VERSION ""

NS_ :

BS_:

BU_: InstrumentalCluster
VAL_TABLE_ PassengerInterierDisplaytbl 3 "NotAvailable" 2 "Errore" 1 "Enable" 0 "Disable" ;
VAL_TABLE_ RearLedDisplayPowertbl 3 "NotAvailable" 2 "Errore" 1 "Enable" 0 "Disable" ;
VAL_TABLE_ DoorSideExterierPowertbl 3 "NotAvailable" 2 "Errore" 1 "Enable" 0 "Disable" ;
VAL_TABLE_ DriverSideInteriorPowertbl 3 "NotAvailable" 2 "Errore" 1 "Enable" 0 "Disable" ;
VAL_TABLE_ DriverSideExterierPowertbl 3 "NotAvailable" 2 "Errore" 1 "Enable" 0 "Disable" ;
VAL_TABLE_ DoorSideInteriorPowertbl 3 "NotAvailable" 2 "Errore" 1 "Enable" 0 "Disable" ;
VAL_TABLE_ FrontLedDisplayPowertbl 3 "NotAvailable" 2 "Errore" 1 "Enable" 0 "Disable" ;
VAL_TABLE_ RebootRequest_TBL 3 "No Action" 2 "Reserved" 1 "RebootRequest" 0 "NoRequest" ;
VAL_TABLE_ ReqeustRebootCancelation_TBL 3 "Not Available" 1 "Started " 0 "Not started" ;
VAL_TABLE_ RequestCanceledReboot_TBL 3 "Not Available" 1 "Canceled" 0 "Not Canceled" ;
VAL_TABLE_ NetToSleepReadyTable 1 "TRUE" 0 "FALSE" ;
VAL_TABLE_ RMReqMode_Table 3 "NA" 2 "FALSE" 1 "TRUE" 0 "NA" ;
VAL_TABLE_ RMModeState_Table 3 "Full recovery" 2 "Flatbed recovery" 1 "Not activated" 0 "NA" ;
VAL_TABLE_ panicAlertDriverReq_Table 3 "NotAvailable" 2 "Reserved" 1 "Panic Alert Requested" 0 "Not requested" ;

BO_ 2348875518 ODM_HMI_SecureStorage: 24 Vector__XXX
 SG_ SecSt_Second_OdometerVal : 160|32@1+ (1,0) [0|0] "" Vector__XXX
 SG_ SecSt_First_OdometerVal : 128|32@1+ (1,0) [0|0] "" Vector__XXX
 SG_ SecSt_Second_Year : 96|7@1+ (1,2000) [2000|2127] "" Vector__XXX
 SG_ SecSt_Second_SPN : 104|20@1+ (1,0) [0|0] "" Vector__XXX
 SG_ SecSt_Second_Seconds : 88|6@1+ (1,0) [0|60] "" Vector__XXX
 SG_ SecSt_Second_Mounth : 124|4@1+ (1,0) [1|12] "" Vector__XXX
 SG_ SecSt_Second_Minutes : 80|6@1+ (1,0) [0|60] "" Vector__XXX
 SG_ SecSt_Second_Hour : 72|5@1+ (1,0) [0|23] "" Vector__XXX
 SG_ SecSt_Second_Day : 64|5@1+ (1,0) [0|31] "" Vector__XXX
 SG_ SecSt_First_Year : 32|7@1+ (1,2000) [2000|2127] "" Vector__XXX
 SG_ SecSt_First_SPN : 40|20@1+ (1,0) [0|1048575] "" Vector__XXX
 SG_ SecSt_First_Seconds : 24|6@1+ (1,0) [0|60] "" Vector__XXX
 SG_ SecSt_First_Mounth : 60|4@1+ (1,0) [1|12] "" Vector__XXX
 SG_ SecSt_First_Minutes : 16|6@1+ (1,0) [0|59] "" Vector__XXX
 SG_ SecSt_First_Hour : 8|5@1+ (1,0) [0|23] "" Vector__XXX
 SG_ SecSt_First_Day : 0|5@1+ (1,0) [1|31] "" Vector__XXX

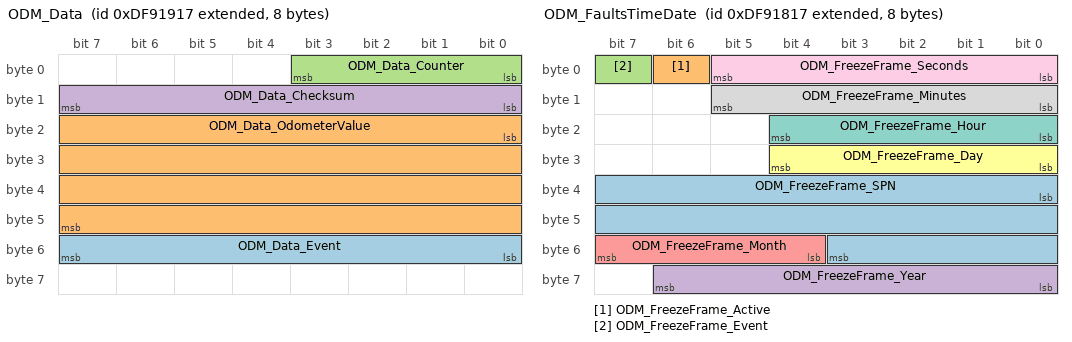
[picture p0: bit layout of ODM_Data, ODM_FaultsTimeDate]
BO_ 2381912343 ODM_Data: 8 Vector__XXX
 SG_ ODM_Data_Event : 48|8@1+ (1,0) [0|0] "" Vector__XXX
 SG_ ODM_Data_OdometerValue : 16|32@1+ (1,0) [0|1700000000] "" Vector__XXX
 SG_ ODM_Data_Counter : 0|4@1+ (1,0) [0|15] "" Vector__XXX
 SG_ ODM_Data_Checksum : 8|8@1+ (1,0) [0|255] "" Vector__XXX

BO_ 2381912087 ODM_FaultsTimeDate: 8 Vector__XXX
 SG_ ODM_FreezeFrame_SPN : 32|20@1+ (1,0) [0|1048575] "" Vector__XXX
 SG_ ODM_FreezeFrame_Active : 6|1@1+ (1,0) [0|1] "" Vector__XXX
 SG_ ODM_FreezeFrame_Event : 7|1@1+ (1,0) [0|1] "" Vector__XXX
 SG_ ODM_FreezeFrame_Year : 56|7@1+ (1,2000) [2000|2127] "" Vector__XXX
 SG_ ODM_FreezeFrame_Month : 52|4@1+ (1,0) [1|12] "" Vector__XXX
 SG_ ODM_FreezeFrame_Day : 24|5@1+ (1,0) [0|31] "" Vector__XXX
 SG_ ODM_FreezeFrame_Hour : 16|5@1+ (1,0) [0|23] "" Vector__XXX
 SG_ ODM_FreezeFrame_Minutes : 8|6@1+ (1,0) [0|59] "" Vector__XXX
 SG_ ODM_FreezeFrame_Seconds : 0|6@1+ (1,0) [0|59] "" Vector__XXX

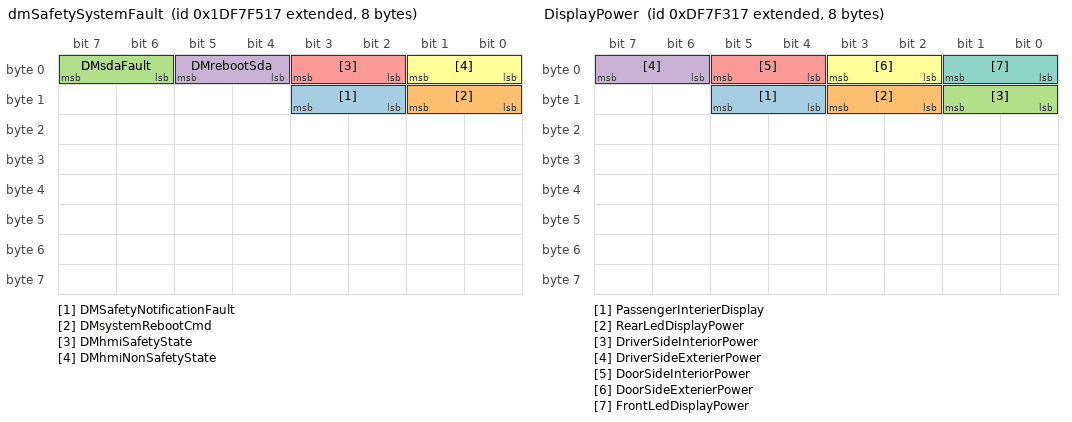
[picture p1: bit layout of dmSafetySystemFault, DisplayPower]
BO_ 2650273047 dmSafetySystemFault: 8 Vector__XXX
 SG_ DMSafetyNotificationFault : 10|2@1+ (1,0) [0|3] "" Vector__XXX
 SG_ DMsystemRebootCmd : 8|2@1+ (1,0) [0|3] "" Vector__XXX
 SG_ DMsdaFault : 6|2@1+ (1,0) [0|3] "" Vector__XXX
 SG_ DMrebootSda : 4|2@1+ (1,0) [0|3] "" Vector__XXX
 SG_ DMhmiSafetyState : 2|2@1+ (1,0) [0|3] "" Vector__XXX
 SG_ DMhmiNonSafetyState : 0|2@1+ (1,0) [0|3] "" Vector__XXX

BO_ 2650747927 HMIConnectivity: 8 Vector__XXX
 SG_ HVPSConnection : 0|1@1+ (1,0) [0|1] "" Vector__XXX

BO_ 2381837079 DisplayPower: 8 Vector__XXX
 SG_ PassengerInterierDisplay : 12|2@1+ (1,0) [0|3] "" Vector__XXX
 SG_ RearLedDisplayPower : 10|2@1+ (1,0) [0|3] "" Vector__XXX
 SG_ DriverSideInteriorPower : 8|2@1+ (1,0) [0|3] "" Vector__XXX
 SG_ DriverSideExterierPower : 6|2@1+ (1,0) [0|3] "" Vector__XXX
 SG_ DoorSideInteriorPower : 4|2@1+ (1,0) [0|3] "" Vector__XXX
 SG_ DoorSideExterierPower : 2|2@1+ (1,0) [0|3] "" Vector__XXX
 SG_ FrontLedDisplayPower : 0|2@1+ (1,0) [0|3] "" Vector__XXX

BO_ 2381836567 UIRebootStop: 8 Vector__XXX
 SG_ RequestCanceledReboot : 0|2@1+ (1,0) [0|3] "" Vector__XXX

BO_ 2381836453 UIRebootRequest: 8 Vector__XXX
 SG_ RebootRequest : 2|2@1+ (1,0) [0|3] "" Vector__XXX
 SG_ ReqeustRebootCancelation : 0|2@1+ (1,0) [0|3] "" Vector__XXX

BO_ 2381846295 VehicleInfo: 8 Vector__XXX
 SG_ CurSpeedLimit : 0|16@1+ (1,0) [0|65535] "" Vector__XXX

BO_ 2381845783 RMRequest: 8 Vector__XXX
 SG_ RMRequest : 0|2@1+ (1,0) [0|3] "" Vector__XXX

BO_ 2381845594 ReqModeState: 8 Vector__XXX
 SG_ RMModeState : 0|2@1+ (1,0) [0|3] "" Vector__XXX

BO_ 2381845159 PanicAlert: 8 Vector__XXX
 SG_ panicAlertDriverReq : 0|2@1+ (1,0) [0|3] "" Vector__XXX

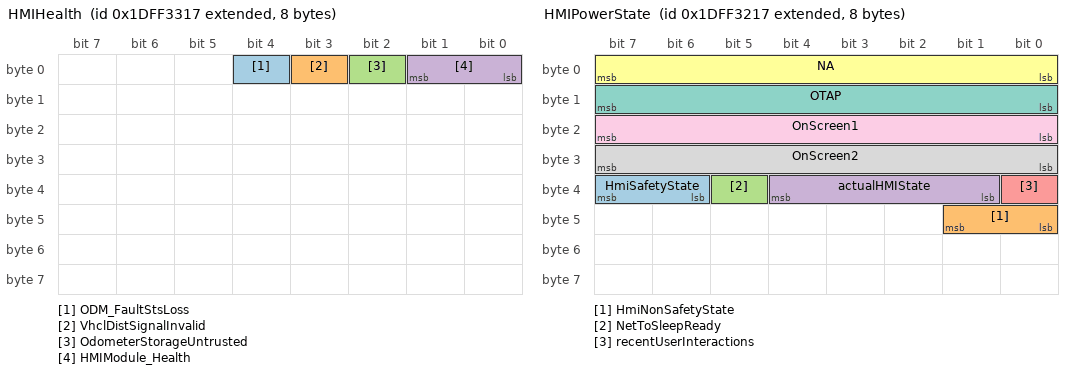
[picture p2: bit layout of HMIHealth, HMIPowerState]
BO_ 2650747671 HMIHealth: 8 Vector__XXX
 SG_ ODM_FaultStsLoss : 4|1@1+ (1,0) [0|1] "" Vector__XXX
 SG_ VhclDistSignalInvalid : 3|1@1+ (1,0) [0|1] "" Vector__XXX
 SG_ OdometerStorageUntrusted : 2|1@1+ (1,0) [0|1] "" Vector__XXX
 SG_ HMIModule_Health : 0|2@1+ (1,0) [0|3] "" Vector__XXX

BO_ 2650747415 HMIPowerState: 8 InstrumentalCluster
 SG_ HmiSafetyState : 38|2@1+ (1,0) [0|3] "" Vector__XXX
 SG_ HmiNonSafetyState : 40|2@1+ (1,0) [0|3] "" Vector__XXX
 SG_ NetToSleepReady : 37|1@1+ (1,0) [0|1] "" Vector__XXX
 SG_ actualHMIState : 33|4@1+ (1,0) [0|15] "" Vector__XXX
 SG_ recentUserInteractions : 32|1@1+ (1,0) [0|1] "" Vector__XXX
 SG_ NA : 0|8@1+ (1,0) [0|1] "" Vector__XXX
 SG_ OTAP : 8|8@1+ (1,0) [0|1] "" Vector__XXX
 SG_ OnScreen2 : 24|8@1+ (1,0) [0|1] "" Vector__XXX
 SG_ OnScreen1 : 16|8@1+ (1,0) [0|1] "" Vector__XXX

CM_ BO_ 2381912343 "Value of odometer travelled distance, stored in HMI backup memory, in meters.
";
CM_ SG_ 2381912343 ODM_Data_Counter "counter signal for E2E protection";
CM_ SG_ 2381912343 ODM_Data_Checksum "Checksum signal for E2E protection";
CM_ BO_ 2381912087 "Data sent from HMI with information about time when particular Odometer DTC has been raised";
CM_ SG_ 2381912087 ODM_FreezeFrame_Event "Which freeze frame is transmited
0 - First security event
1 - Last security event";
CM_ SG_ 2650273047 DMSafetyNotificationFault "CAN Timeout DM";
CM_ SG_ 2650273047 DMsystemRebootCmd "System reboot status";
CM_ SG_ 2650273047 DMsdaFault "SDA fault status";
CM_ SG_ 2650273047 DMrebootSda "Reboot SDA status";
CM_ SG_ 2650273047 DMhmiSafetyState "Safety State system status";
CM_ SG_ 2650273047 DMhmiNonSafetyState "Non Safety State system status";
CM_ SG_ 2650747671 HMIModule_Health "Overal HMI health status";
CM_ BO_ 2650747415 "Power state of HMI as well as OTA state";
CM_ SG_ 2650747415 recentUserInteractions "Any of possible user interactions with HMI was detected during the configured time interval (Boolean value)
1- True,
0 -False";
CM_ SG_ 2650747415 NA "State: 0 - NA, means others flags isn't valid;  1 - OK, means others flags are valid";
CM_ SG_ 2650747415 OTAP "OTA in progress: 1 - true; 0 - false";
CM_ SG_ 2650747415 OnScreen2 "Screen 2 is ON: 1 - true; 0 - false";
CM_ SG_ 2650747415 OnScreen1 "Screen 1 is ON: 1 - true; 0 - false";
BA_DEF_ SG_  "SPN" INT 0 524287;
BA_DEF_ SG_  "GenSigEVName" STRING ;
BA_DEF_ SG_  "GenSigILSupport" ENUM  "No","Yes";
BA_DEF_ SG_  "GenSigSendType" ENUM  "Cyclic","OnWrite","OnWriteWithRepetition","OnChange","OnChangeWithRepetition","IfActive","IfActiveWithRepetition","NoSigSendType";
BA_DEF_ SG_  "SigType" ENUM  "Default","Range","RangeSigned","ASCII","Discrete","Control","ReferencePGN","DTC","StringDelimiter","StringLength","StringLengthControl","MessageCounter","MessageChecksum";
BA_DEF_ BO_  "VFrameFormat" ENUM  "StandardCAN","ExtendedCAN","reserved","J1939PG";
BA_DEF_ BO_  "GenMsgSendType" ENUM  "cyclic","NotUsed","NotUsed","NotUsed","NotUsed","NotUsed","NotUsed","IfActive","noMsgSendType";
BA_DEF_ BO_  "GenMsgRequestable" INT 0 1;
BA_DEF_ BO_  "GenMsgILSupport" ENUM  "No","Yes";
BA_DEF_ BU_  "NmStationAddress" INT 0 255;
BA_DEF_  "ProtocolType" STRING ;
BA_DEF_  "DBName" STRING ;
BA_DEF_  "BusType" STRING ;
BA_DEF_ BO_  "GenMsgCycleTime" INT 0 65535;
BA_DEF_ SG_  "GenSigStartValue" FLOAT -3.4E+038 3.4E+038;
BA_DEF_DEF_  "SPN" 0;
BA_DEF_DEF_  "GenSigEVName" "Env@Nodename_@Signame";
BA_DEF_DEF_  "GenSigILSupport" "Yes";
BA_DEF_DEF_  "GenSigSendType" "NoSigSendType";
BA_DEF_DEF_  "SigType" "Default";
BA_DEF_DEF_  "VFrameFormat" "J1939PG";
BA_DEF_DEF_  "GenMsgSendType" "noMsgSendType";
BA_DEF_DEF_  "GenMsgRequestable" 1;
BA_DEF_DEF_  "GenMsgILSupport" "Yes";
BA_DEF_DEF_  "NmStationAddress" 254;
BA_DEF_DEF_  "ProtocolType" "";
BA_DEF_DEF_  "DBName" "";
BA_DEF_DEF_  "BusType" "CAN";
BA_DEF_DEF_  "GenMsgCycleTime" 0;
BA_DEF_DEF_  "GenSigStartValue" 0;
BA_ "ProtocolType" "J1939";
BA_ "DBName" "ArrivalHMI";
BA_ "NmStationAddress" BU_ InstrumentalCluster 23;
BA_ "GenMsgSendType" BO_ 2381912343 0;
BA_ "GenMsgCycleTime" BO_ 2381912343 100;
BA_ "GenMsgSendType" BO_ 2381912087 0;
BA_ "GenMsgCycleTime" BO_ 2381912087 1000;
BA_ "GenMsgCycleTime" BO_ 2381837079 100;
BA_ "GenMsgSendType" BO_ 2381837079 0;
BA_ "GenMsgCycleTime" BO_ 2381836567 100;
BA_ "GenMsgSendType" BO_ 2381836567 0;
BA_ "GenMsgCycleTime" BO_ 2381836453 100;
BA_ "GenMsgSendType" BO_ 2381836453 0;
BA_ "GenMsgCycleTime" BO_ 2381846295 100;
BA_ "GenMsgSendType" BO_ 2381846295 0;
BA_ "GenMsgCycleTime" BO_ 2381845783 100;
BA_ "GenMsgSendType" BO_ 2381845783 0;
BA_ "GenMsgCycleTime" BO_ 2381845594 100;
BA_ "GenMsgSendType" BO_ 2381845594 0;
BA_ "GenMsgCycleTime" BO_ 2381845159 1000;
BA_ "GenMsgCycleTime" BO_ 2650747415 250;
BA_ "GenSigStartValue" SG_ 2348875518 SecSt_Second_Year 24;
BA_ "GenSigStartValue" SG_ 2348875518 SecSt_Second_Mounth 1;
BA_ "GenSigStartValue" SG_ 2348875518 SecSt_First_Year 24;
BA_ "GenSigStartValue" SG_ 2348875518 SecSt_First_Mounth 1;
BA_ "GenSigStartValue" SG_ 2348875518 SecSt_First_Day 1;
BA_ "SigType" SG_ 2381912343 ODM_Data_Counter 11;
BA_ "SigType" SG_ 2381912343 ODM_Data_Checksum 12;
BA_ "GenSigStartValue" SG_ 2381912087 ODM_FreezeFrame_Year 23;
BA_ "GenSigStartValue" SG_ 2381912087 ODM_FreezeFrame_Month 1;
BA_ "GenSigStartValue" SG_ 2381912087 ODM_FreezeFrame_Day 1;
BA_ "SPN" SG_ 2650273047 DMSafetyNotificationFault 519768;
BA_ "SPN" SG_ 2650273047 DMsystemRebootCmd 519771;
BA_ "SPN" SG_ 2650273047 DMsdaFault 519770;
BA_ "SPN" SG_ 2650273047 DMrebootSda 519769;
BA_ "SPN" SG_ 2650273047 DMhmiSafetyState 519773;
BA_ "SPN" SG_ 2650273047 DMhmiNonSafetyState 519772;
BA_ "SPN" SG_ 2650747927 HVPSConnection 519757;
BA_ "GenSigStartValue" SG_ 2381837079 PassengerInterierDisplay 3;
BA_ "GenSigStartValue" SG_ 2381837079 RearLedDisplayPower 3;
BA_ "GenSigStartValue" SG_ 2381837079 DriverSideInteriorPower 3;
BA_ "GenSigStartValue" SG_ 2381837079 DriverSideExterierPower 3;
BA_ "GenSigStartValue" SG_ 2381837079 DoorSideInteriorPower 3;
BA_ "GenSigStartValue" SG_ 2381837079 DoorSideExterierPower 3;
BA_ "GenSigStartValue" SG_ 2381837079 FrontLedDisplayPower 3;
BA_ "GenSigStartValue" SG_ 2381836567 RequestCanceledReboot 3;
BA_ "GenSigStartValue" SG_ 2381836453 RebootRequest 3;
BA_ "GenSigStartValue" SG_ 2381836453 ReqeustRebootCancelation 3;
BA_ "GenSigStartValue" SG_ 2381845159 panicAlertDriverReq 3;
BA_ "SPN" SG_ 2650747671 ODM_FaultStsLoss 519797;
BA_ "SPN" SG_ 2650747671 VhclDistSignalInvalid 519797;
BA_ "SigType" SG_ 2650747671 VhclDistSignalInvalid 7;
BA_ "SPN" SG_ 2650747671 OdometerStorageUntrusted 519798;
BA_ "SigType" SG_ 2650747671 OdometerStorageUntrusted 7;
BA_ "GenSigStartValue" SG_ 2650747671 HMIModule_Health 3;
VAL_ 2381912087 ODM_FreezeFrame_Event 1 "Last security event" 0 "First security event" ;
VAL_ 2650273047 DMSafetyNotificationFault 3 "NA" 2 "Reserved" 1 "NOK" 0 "OK" ;
VAL_ 2650273047 DMsystemRebootCmd 3 "NA" 2 "Reserved" 1 "NOK" 0 "OK" ;
VAL_ 2650273047 DMsdaFault 3 "NA" 2 "Reserved" 1 "NOK" 0 "OK" ;
VAL_ 2650273047 DMrebootSda 3 "NA" 2 "Reserved" 1 "NOK" 0 "OK" ;
VAL_ 2650273047 DMhmiSafetyState 3 "NA" 2 "Reserved" 1 "NOK" 0 "OK" ;
VAL_ 2650273047 DMhmiNonSafetyState 3 "NA" 2 "Reserved" 1 "NOK" 0 "OK" ;
VAL_ 2381837079 PassengerInterierDisplay 3 "NotAvailable" 2 "Errore" 1 "Enable" 0 "Disable" ;
VAL_ 2381837079 RearLedDisplayPower 3 "NotAvailable" 2 "Errore" 1 "Enable" 0 "Disable" ;
VAL_ 2381837079 DriverSideInteriorPower 3 "NotAvailable" 2 "Errore" 1 "Enable" 0 "Disable" ;
VAL_ 2381837079 DriverSideExterierPower 3 "NotAvailable" 2 "Errore" 1 "Enable" 0 "Disable" ;
VAL_ 2381837079 DoorSideInteriorPower 3 "NotAvailable" 2 "Errore" 1 "Enable" 0 "Disable" ;
VAL_ 2381837079 DoorSideExterierPower 3 "NotAvailable" 2 "Errore" 1 "Enable" 0 "Disable" ;
VAL_ 2381837079 FrontLedDisplayPower 3 "NotAvailable" 2 "Errore" 1 "Enable" 0 "Disable" ;
VAL_ 2381836567 RequestCanceledReboot 3 "Not Available" 1 "Canceled" 0 "Not Canceled" ;
VAL_ 2381836453 RebootRequest 3 "No Action" 2 "Reserved" 1 "RebootRequest" 0 "NoRequest" ;
VAL_ 2381836453 ReqeustRebootCancelation 3 "Not Available" 1 "Started " 0 "Not started" ;
VAL_ 2381845783 RMRequest 3 "NA" 2 "FALSE" 1 "TRUE" 0 "NA" ;
VAL_ 2381845594 RMModeState 3 "Full recovery" 2 "Flatbed recovery" 1 "Not activated" 0 "NA" ;
VAL_ 2381845159 panicAlertDriverReq 3 "NotAvailable" 2 "Reserved" 1 "Panic Alert Requested" 0 "Not requested" ;
VAL_ 2650747671 HMIModule_Health 3 "NotAvailable" 2 "Reserved" 1 "NOK" 0 "OK" ;
VAL_ 2650747415 HmiSafetyState 3 "NA" 2 "ERROR" 1 "OK" 0 "NOK" ;
VAL_ 2650747415 HmiNonSafetyState 3 "NA" 2 "ERROR" 1 "OK" 0 "NOK" ;
VAL_ 2650747415 NetToSleepReady 1 "TRUE" 0 "FALSE" ;
VAL_ 2650747415 actualHMIState 14 "Error" 5 "InHibernation" 9 "SafetyReady" 7 "SafetyFail" 8 "Maintenance" 4 "SoftSleepMode" 1 "PoweringUp" 15 "NotAvailable" 6 "NonSafetyFault" 3 "FullyOperable" 2 "BootingUp" 0 "PowerOff" ;
